AUTOSAR XML (schema 4-0-3)
standard types defined: Boolean, UInt16, UInt8
package /AUTOSAR_Platform/DataConstrs
  range DC_Boolean: raw 0..1
  range DC_UInt16: raw 0..65535
  range DC_UInt8: raw 0..255
package /PATAC/MSM/ComponentTypes
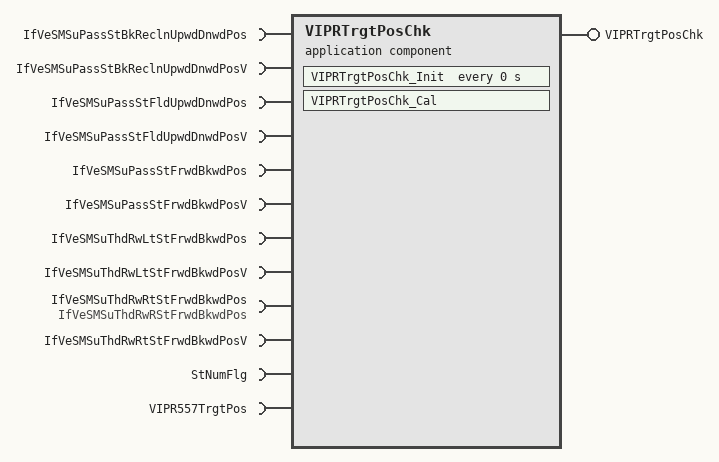
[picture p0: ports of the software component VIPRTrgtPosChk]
  application sw component type VIPRTrgtPosChk
    provide port VIPRTrgtPosChk: server-com-spec{operation=Cal, queue-length=1}, provided-interface=VIPRTrgtPosChk
    12 x require port:
      IfVeSMSuPassStBkReclnUpwdDnwdPos: nonqueued-receiver-com-spec{data-element=IfVeSMSuPassStBkReclnUpwdDnwdPos/Val, filter=data-filter-type=ALWAYS, init-value=0}, required-interface=IfVeSMSuPassStBkReclnUpwdDnwdPos
      IfVeSMSuPassStBkReclnUpwdDnwdPosV: nonqueued-receiver-com-spec{data-element=IfVeSMSuPassStBkReclnUpwdDnwdPosV/Val, filter=data-filter-type=ALWAYS, init-value=0}, required-interface=IfVeSMSuPassStBkReclnUpwdDnwdPosV
      IfVeSMSuPassStFldUpwdDnwdPos: nonqueued-receiver-com-spec{data-element=IfVeSMSuPassStFldUpwdDnwdPos/Val, filter=data-filter-type=ALWAYS, init-value=0}, required-interface=IfVeSMSuPassStFldUpwdDnwdPos
      IfVeSMSuPassStFldUpwdDnwdPosV: nonqueued-receiver-com-spec{data-element=IfVeSMSuPassStFldUpwdDnwdPosV/Val, filter=data-filter-type=ALWAYS, init-value=0}, required-interface=IfVeSMSuPassStFldUpwdDnwdPosV
      IfVeSMSuPassStFrwdBkwdPos: nonqueued-receiver-com-spec{data-element=IfVeSMSuPassStFrwdBkwdPos/Val, filter=data-filter-type=ALWAYS, init-value=0}, required-interface=IfVeSMSuPassStFrwdBkwdPos
      IfVeSMSuPassStFrwdBkwdPosV: nonqueued-receiver-com-spec{data-element=IfVeSMSuPassStFrwdBkwdPosV/Val, filter=data-filter-type=ALWAYS, init-value=0}, required-interface=IfVeSMSuPassStFrwdBkwdPosV
      IfVeSMSuThdRwLtStFrwdBkwdPos: nonqueued-receiver-com-spec{data-element=IfVeSMSuThdRwLtStFrwdBkwdPos/Val, filter=data-filter-type=ALWAYS, init-value=0}, required-interface=IfVeSMSuThdRwLtStFrwdBkwdPos
      IfVeSMSuThdRwLtStFrwdBkwdPosV: nonqueued-receiver-com-spec{data-element=IfVeSMSuThdRwLtStFrwdBkwdPosV/Val, filter=data-filter-type=ALWAYS, init-value=0}, required-interface=IfVeSMSuThdRwLtStFrwdBkwdPosV
      IfVeSMSuThdRwRtStFrwdBkwdPos: nonqueued-receiver-com-spec{data-element=IfVeSMSuThdRwRStFrwdBkwdPos/Val, filter=data-filter-type=ALWAYS, init-value=0}, required-interface=IfVeSMSuThdRwRStFrwdBkwdPos
      IfVeSMSuThdRwRtStFrwdBkwdPosV: nonqueued-receiver-com-spec{data-element=IfVeSMSuThdRwRtStFrwdBkwdPosV/Val, filter=data-filter-type=ALWAYS, init-value=0}, required-interface=IfVeSMSuThdRwRtStFrwdBkwdPosV
      StNumFlg: required-interface=StNumFlg
        required-com-specs:
          data-element=Is4s, filter=data-filter-type=ALWAYS, init-value=0
          data-element=Is6s, filter=data-filter-type=ALWAYS, init-value=0
          data-element=Is6s7s, filter=data-filter-type=ALWAYS, init-value=0
          data-element=Is7s, filter=data-filter-type=ALWAYS, init-value=0
      VIPR557TrgtPos: required-com-specs=[Get, Set], required-interface=VIPR557TrgtPos
    behavior VIPRTrgtPosChk_InternalBehavior
      operation invoked event OIT_VIPRTrgtPosChk_Cal_VIPRTrgtPosChk_Cal: start-on-event=VIPRTrgtPosChk_Cal, operation=VIPRTrgtPosChk.Cal
      timing event VIPRTrgtPosChk_InitEvent: start-on-event=VIPRTrgtPosChk_Init, period=0
      runnable VIPRTrgtPosChk_Cal
        data-receive-point-by-arguments:
          14 x access:
            REC_IfVeSMSuPassStBkReclnUpwdDnwdPos_Val: accessed-variable=IfVeSMSuPassStBkReclnUpwdDnwdPos.Val
            REC_IfVeSMSuPassStBkReclnUpwdDnwdPosV_Val: accessed-variable=IfVeSMSuPassStBkReclnUpwdDnwdPosV.Val
            REC_IfVeSMSuPassStFldUpwdDnwdPos_Val: accessed-variable=IfVeSMSuPassStFldUpwdDnwdPos.Val
            REC_IfVeSMSuPassStFldUpwdDnwdPosV_Val: accessed-variable=IfVeSMSuPassStFldUpwdDnwdPosV.Val
            REC_IfVeSMSuPassStFrwdBkwdPos_Val: accessed-variable=IfVeSMSuPassStFrwdBkwdPos.Val
            REC_IfVeSMSuPassStFrwdBkwdPosV_Val: accessed-variable=IfVeSMSuPassStFrwdBkwdPosV.Val
            REC_IfVeSMSuThdRwLtStFrwdBkwdPos_Val: accessed-variable=IfVeSMSuThdRwLtStFrwdBkwdPos.Val
            REC_IfVeSMSuThdRwLtStFrwdBkwdPosV_Val: accessed-variable=IfVeSMSuThdRwLtStFrwdBkwdPosV.Val
            REC_IfVeSMSuThdRwRtStFrwdBkwdPos_Val: accessed-variable=IfVeSMSuThdRwRtStFrwdBkwdPos.Val
            REC_IfVeSMSuThdRwRtStFrwdBkwdPosV_Val: accessed-variable=IfVeSMSuThdRwRtStFrwdBkwdPosV.Val
            REC_StNumFlg_Is4s: accessed-variable=StNumFlg.Is4s
            REC_StNumFlg_Is6s: accessed-variable=StNumFlg.Is6s
            REC_StNumFlg_Is6s7s: accessed-variable=StNumFlg.Is6s7s
            REC_StNumFlg_Is7s: accessed-variable=StNumFlg.Is7s
        sync call SC_VIPR557TrgtPos_Set: operation=VIPR557TrgtPos.Set, timeout=0
      runnable VIPRTrgtPosChk_Init
  swc implementation VIPRTrgtPosChk_Implementation: behavior=VIPRTrgtPosChk_InternalBehavior
    code-descriptors:
      code Default: artifact-descriptors=autosar-engineering-object={short-label=Default, category=SWSRC}
package /PATAC/MSM/Intervene/PortInterfaces
  client server interface VIPRTrgtPosChk  # PosAvl：1模式可用 PosAvl：0模式不可用
    operation Cal
      arg PosAvl: type=UInt8, direction=OUT, server-argument-impl-policy=USE-ARGUMENT-TYPE
package /PATAC/MSM/ModeAdjust/Interfaces
  5 x sender receiver interface:
    IfVeSMSuPassStBkReclnUpwdDnwdPosV: invalidation-policy{data-element=IfVeSMSuPassStBkReclnUpwdDnwdPosV/Val, handle-invalid=DONT-INVALIDATE}
      data Val: type=Boolean
    IfVeSMSuPassStFldUpwdDnwdPosV: invalidation-policy{data-element=IfVeSMSuPassStFldUpwdDnwdPosV/Val, handle-invalid=DONT-INVALIDATE}
      data Val: type=Boolean
    IfVeSMSuPassStFrwdBkwdPosV: invalidation-policy{data-element=IfVeSMSuPassStFrwdBkwdPosV/Val, handle-invalid=DONT-INVALIDATE}
      data Val: type=Boolean
    IfVeSMSuThdRwLtStFrwdBkwdPosV: invalidation-policy{data-element=IfVeSMSuThdRwLtStFrwdBkwdPosV/Val, handle-invalid=DONT-INVALIDATE}
      data Val: type=Boolean
    IfVeSMSuThdRwRtStFrwdBkwdPosV: invalidation-policy{data-element=IfVeSMSuThdRwRtStFrwdBkwdPosV/Val, handle-invalid=DONT-INVALIDATE}
      data Val: type=Boolean
package /PATAC/MSM/ModeAdjust/PortInterface
  client server interface VIPR557TrgtPos
    operation Get
      5 x arg, all with type=UInt16, direction=OUT, server-argument-impl-policy=USE-ARGUMENT-TYPE:
        SecRwLtStBkReclnTrgtPos
        SecRwLtStZeroTrgtPos
        SecRwLtStLgrstUpwdDnwdTrgtPos
        SecRwLtStLgrstInwdOtwdTrgtPos
        SecRwLtStFwdBkwdTrgtPos
    operation Set
      5 x arg, all with type=UInt16, direction=IN, server-argument-impl-policy=USE-ARGUMENT-TYPE:
        SecRwLtStBkReclnTrgtPos
        SecRwLtStZeroTrgtPos
        SecRwLtStLgrstUpwdDnwdTrgtPos
        SecRwLtStLgrstInwdOtwdTrgtPos
        SecRwLtStFwdBkwdTrgtPos
  sender receiver interface IfVeSMSuPassStFldUpwdDnwdPos: invalidation-policy{data-element=IfVeSMSuPassStFldUpwdDnwdPos/Val, handle-invalid=DONT-INVALIDATE}
    data Val: type=UInt16
  sender receiver interface StNumFlg
    4 x data, all with type=Boolean:
      Is4s
      Is6s
      Is6s7s
      Is7s
    invalidation-policys:
      data-element=Is4s, handle-invalid=DONT-INVALIDATE
      data-element=Is6s, handle-invalid=DONT-INVALIDATE
      data-element=Is6s7s, handle-invalid=DONT-INVALIDATE
      data-element=Is7s, handle-invalid=DONT-INVALIDATE
package /PATAC/MSM/PortInterfaces
  4 x sender receiver interface:
    IfVeSMSuPassStBkReclnUpwdDnwdPos: invalidation-policy{data-element=IfVeSMSuPassStBkReclnUpwdDnwdPos/Val, handle-invalid=DONT-INVALIDATE}
      data Val: type=UInt16
    IfVeSMSuPassStFrwdBkwdPos: invalidation-policy{data-element=IfVeSMSuPassStFrwdBkwdPos/Val, handle-invalid=DONT-INVALIDATE}
      data Val: type=UInt16
    IfVeSMSuThdRwLtStFrwdBkwdPos: invalidation-policy{data-element=IfVeSMSuThdRwLtStFrwdBkwdPos/Val, handle-invalid=DONT-INVALIDATE}
      data Val: type=UInt16
    IfVeSMSuThdRwRStFrwdBkwdPos: invalidation-policy{data-element=IfVeSMSuThdRwRStFrwdBkwdPos/Val, handle-invalid=DONT-INVALIDATE}
      data Val: type=UInt16
